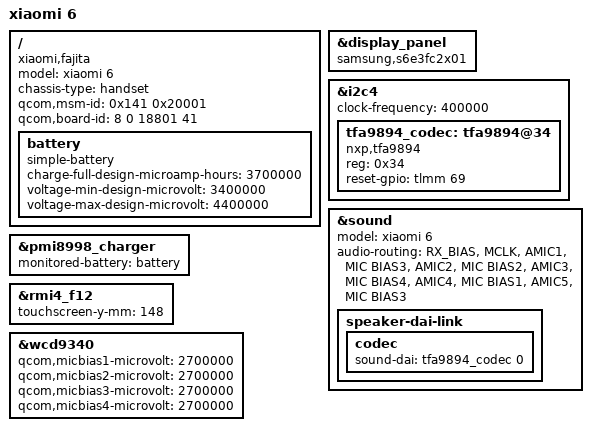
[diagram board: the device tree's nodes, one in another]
// SPDX-License-Identifier: GPL-2.0
/*
 * msm8998 xiaomi 6 (fajita) device tree.
 *
 * Copyright (c) 2020, The Linux Foundation. All rights reserved.
 */

#include "msm8998-xiaomi-common.dtsi"

/ {
	model = "xiaomi 6";
	compatible = "xiaomi,fajita", "qcom,msm8998";
	chassis-type = "handset";
	qcom,msm-id = <0x141 0x20001>;
	qcom,board-id = <8 0 18801 41>;

	battery: battery {
		compatible = "simple-battery";

		charge-full-design-microamp-hours = <3700000>;
		voltage-min-design-microvolt = <3400000>;
		voltage-max-design-microvolt = <4400000>;
	};
};

&display_panel {
	status = "okay";

	compatible = "samsung,s6e3fc2x01";
};

&i2c4 {
	status = "okay";
	clock-frequency = <400000>;

	tfa9894_codec: tfa9894@34 {
		#sound-dai-cells = <1>;
		compatible = "nxp,tfa9894";
		reg = <0x34>;
		reset-gpio = <&tlmm 69 0>;
	};
};

&sound {
	model = "xiaomi 6";
	audio-routing = "RX_BIAS", "MCLK",
			"AMIC1", "MIC BIAS3",
			"AMIC2", "MIC BIAS2",
			"AMIC3", "MIC BIAS4",
			"AMIC4", "MIC BIAS1",
			"AMIC5", "MIC BIAS3";

	speaker-dai-link {
		codec {
			sound-dai = <&tfa9894_codec 0>;
		};
	};
};

&pmi8998_charger {
	monitored-battery = <&battery>;
};

&rmi4_f12 {
	touchscreen-y-mm = <148>;
};

&wcd9340 {
	qcom,micbias1-microvolt = <2700000>;
	qcom,micbias2-microvolt = <2700000>;
	qcom,micbias3-microvolt = <2700000>;
	qcom,micbias4-microvolt = <2700000>;
};
